VERSION ""

BO_ 514 BODY_COMMAND: 4 EON
  SG_ SPEED : 7|16@0+ (1,-32768) [-32768|32767] "" BODYBOARD
  SG_ STEER : 23|16@0+ (1,-32768) [-32768|32767] "" BODYBOARD

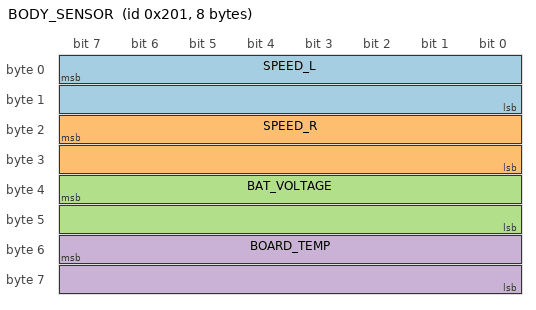
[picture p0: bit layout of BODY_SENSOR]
BO_ 513 BODY_SENSOR: 8 BODYBOARD
  SG_ SPEED_L : 7|16@0+ (1,-32768) [-32768|32767] "" EON
  SG_ SPEED_R : 23|16@0+ (1,-32768) [-32768|32767] "" EON
  SG_ BAT_VOLTAGE : 39|16@0+ (1,-32768) [-32768|32767] "" EON
  SG_ BOARD_TEMP : 55|16@0+ (1,-32768) [-32768|32767] "" EON
